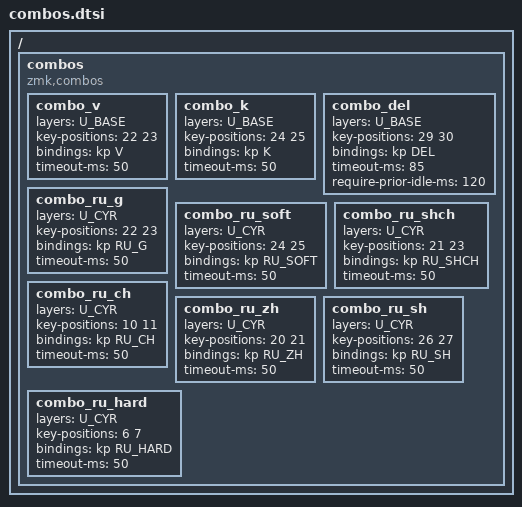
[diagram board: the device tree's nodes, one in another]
#include "macros.h"

/ {
    combos {
        compatible = "zmk,combos";

        // V = C(22) + D(23)
        combo_v {
            layers = <U_BASE>;
            key-positions = <22 23>;
            bindings = <&kp V>;
            timeout-ms = <50>;
        };

        // K = H(24) + ,(25)
        combo_k {
            layers = <U_BASE>;
            key-positions = <24 25>;
            bindings = <&kp K>;
            timeout-ms = <50>;
        };

        // DEL = thumbs (29 + 30)
        combo_del {
            layers = <U_BASE>;
            key-positions = <29 30>;
            bindings = <&kp DEL>;
            timeout-ms = <85>;
            require-prior-idle-ms = <120>;
        };

        // RU_G = Р(22) + М(23)
        combo_ru_g {
            layers = <U_CYR>;
            key-positions = <22 23>;
            bindings = <&kp RU_G>;
            timeout-ms = <50>;
        };

        // RU_SOFT = У(24) + Б(25)
        combo_ru_soft {
            layers = <U_CYR>;
            key-positions = <24 25>;
            bindings = <&kp RU_SOFT>;
            timeout-ms = <50>;
        };

        // RU_SHCH = М(23) + П(21)
        combo_ru_shch {
            layers = <U_CYR>;
            key-positions = <21 23>;
            bindings = <&kp RU_SHCH>;
            timeout-ms = <50>;
        };

        // RU_CH = З(10) + В(11)
        combo_ru_ch {
            layers = <U_CYR>;
            key-positions = <10 11>;
            bindings = <&kp RU_CH>;
            timeout-ms = <50>;
        };

        // RU_ZH = Х(20) + П(21)
        combo_ru_zh {
            layers = <U_CYR>;
            key-positions = <20 21>;
            bindings = <&kp RU_ZH>;
            timeout-ms = <50>;
        };

        // RU_SH = Ю(26) + .(27)
        combo_ru_sh {
            layers = <U_CYR>;
            key-positions = <26 27>;
            bindings = <&kp RU_SH>;
            timeout-ms = <50>;
        };

        // RU_HARD = Ы(6) + Я(7)
        combo_ru_hard {
            layers = <U_CYR>;
            key-positions = <6 7>;
            bindings = <&kp RU_HARD>;
            timeout-ms = <50>;
        };
    };
};
